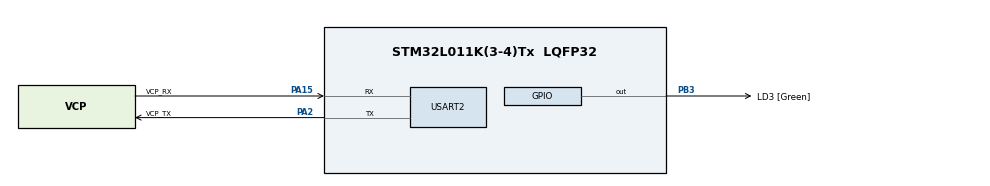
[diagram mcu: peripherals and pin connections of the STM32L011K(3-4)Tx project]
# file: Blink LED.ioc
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Mcu.Family=STM32L0
Mcu.Name=STM32L011K(3-4)Tx
Mcu.Package=LQFP32
PA13.GPIO_Label=TMS
PA13.Mode=Serial_Wire
PA13.Signal=SYS_SWDIO
PA14.GPIO_Label=TCK
PA14.Mode=Serial_Wire
PA14.Signal=SYS_SWCLK
PA15.GPIO_Label=VCP_RX
PA15.Mode=Asynchronous
PA15.Signal=USART2_RX
PA2.GPIO_Label=VCP_TX
PA2.Mode=Asynchronous
PA2.Signal=USART2_TX
PB3.GPIO_Label=LD3 [Green]
PB3.Signal=GPIO_Output
PC14-OSC32_IN.Mode=LSE-External-Oscillator
PC14-OSC32_IN.Signal=RCC_OSC32_IN
PC15-OSC32_OUT.Mode=LSE-External-Oscillator
PC15-OSC32_OUT.Signal=RCC_OSC32_OUT
ProjectManager.HeapSize=0x200
ProjectManager.StackSize=0x400
ProjectManager.TargetToolchain=STM32CubeIDE
RCC.ADCFreq_Value=16000000
RCC.AHBFreq_Value=32000000
RCC.APB1Freq_Value=32000000
RCC.APB1TimFreq_Value=32000000
RCC.APB2Freq_Value=32000000
RCC.APB2TimFreq_Value=32000000
RCC.HCLKFreq_Value=32000000
RCC.HSE_VALUE=8000000
RCC.HSI16_VALUE=16000000
RCC.HSI48_VALUE=48000000
RCC.HSI_VALUE=16000000
RCC.MSI_VALUE=2097000
RCC.PLLMUL=RCC_PLLMUL_4
RCC.SYSCLKFreq_VALUE=32000000
RCC.SYSCLKSource=RCC_SYSCLKSOURCE_PLLCLK
RCC.VCOOutputFreq_Value=64000000
SYS.PowerMode=PWR_LDO_SUPPLY
USART2.VirtualMode-Asynchronous=VM_ASYNC
VP_SYS_VS_LPOM.Mode=PowerOptimisation
board=NUCLEO-L011K4

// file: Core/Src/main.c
/* USER CODE BEGIN Header */
/**
  ******************************************************************************
  * @file           : main.c
  * @brief          : Main program body
  ******************************************************************************
  * @attention
  *
  * Copyright (c) 2024 STMicroelectronics.
  * All rights reserved.
  *
  * This software is licensed under terms that can be found in the LICENSE file
  * in the root directory of this software component.
  * If no LICENSE file comes with this software, it is provided AS-IS.
  *
  ******************************************************************************
  */
/* USER CODE END Header */
#include "main.h"
#include "usart.h"
#include "gpio.h"

void SystemClock_Config(void);

int main(void)
{

  /* MCU Configuration--------------------------------------------------------*/

  /* Reset of all peripherals, Initializes the Flash interface and the Systick. */
  LL_APB2_GRP1_EnableClock(LL_APB2_GRP1_PERIPH_SYSCFG);
  LL_APB1_GRP1_EnableClock(LL_APB1_GRP1_PERIPH_PWR);

  /* Configure the system clock */
  SystemClock_Config();

  /* Initialize all configured peripherals */
  MX_GPIO_Init();
  MX_USART2_UART_Init();

  /* Infinite loop */
  /* USER CODE BEGIN WHILE */
  while (1)
  {
	  LL_mDelay(250);
	  LL_GPIO_TogglePin(LD3_GPIO_Port, LD3_Pin);
    /* USER CODE END WHILE */

  }
}

void SystemClock_Config(void)
{
  LL_FLASH_SetLatency(LL_FLASH_LATENCY_1);
  while(LL_FLASH_GetLatency()!= LL_FLASH_LATENCY_1)
  {
  }
  LL_PWR_SetRegulVoltageScaling(LL_PWR_REGU_VOLTAGE_SCALE1);
  while (LL_PWR_IsActiveFlag_VOS() != 0)
  {
  }
  LL_RCC_HSI_Enable();

   /* Wait till HSI is ready */
  while(LL_RCC_HSI_IsReady() != 1)
  {

  }
  LL_RCC_HSI_SetCalibTrimming(16);
  LL_RCC_PLL_ConfigDomain_SYS(LL_RCC_PLLSOURCE_HSI, LL_RCC_PLL_MUL_4, LL_RCC_PLL_DIV_2);
  LL_RCC_PLL_Enable();

   /* Wait till PLL is ready */
  while(LL_RCC_PLL_IsReady() != 1)
  {

  }
  LL_RCC_SetAHBPrescaler(LL_RCC_SYSCLK_DIV_1);
  LL_RCC_SetAPB1Prescaler(LL_RCC_APB1_DIV_1);
  LL_RCC_SetAPB2Prescaler(LL_RCC_APB2_DIV_1);
  LL_RCC_SetSysClkSource(LL_RCC_SYS_CLKSOURCE_PLL);

   /* Wait till System clock is ready */
  while(LL_RCC_GetSysClkSource() != LL_RCC_SYS_CLKSOURCE_STATUS_PLL)
  {

  }

  LL_Init1msTick(32000000);

  LL_SetSystemCoreClock(32000000);
  LL_RCC_SetUSARTClockSource(LL_RCC_USART2_CLKSOURCE_PCLK1);
}

void Error_Handler(void)
{
  __disable_irq();
  while (1)
  {
  }
}
